# a34m41x register map
Vendor: ABOV Semiconductor Co., Ltd.; File version: 1.0
CPU: CM4 r0p1, little endian, MPU, FPU, VTOR, 4 interrupt priority bits
Registers are 32-bit, read-write, reset 0x0 unless marked. A register's access mark holds for its fields unless they carry their own. Offsets are from the block's base; [hi:lo] are bit positions; {n}, {i} and the like mark numbered series.

## PORTEN — General Port Access Enable
Base 0x40001FF0
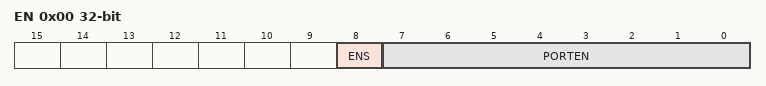
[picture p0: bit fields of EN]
0x00 EN wo (reset mask 0xFF) — Port Access Enable Register
  [8] ENS ro — Enable Status Bit
  [7:0] PORTEN — Port Access Enable bit, write sequence 0x15, 0x51

## DFMC — DATA FLASH MEMORY CONTROLLER
Base 0x41001000
0x00 CONF — Flash Memory Control Register
  [3:0] LATENCY — Flash Wait Value Bits
0x04 FLSKEY — Flash Memory Access Key Register
  [31:0] FKEY — Flash Memory Access Key, KEY1(0x01234567) -> KEY2(0x12345678) -> KEY3(0x23456789)
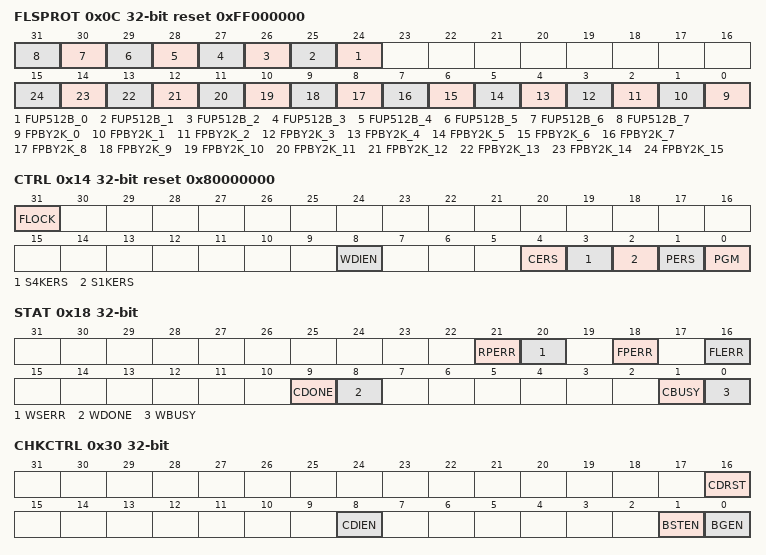
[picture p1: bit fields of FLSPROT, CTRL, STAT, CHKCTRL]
0x0C FLSPROT reset 0xFF000000 — Flash Memory Protection Register
  [n+24] FUP512B_{n} (n=0..7) — Flash upper 4KB Unprotection
  [n] FPBY2K_{n} (n=0..15) — Flash 2KB Protection
0x14 CTRL reset 0x80000000 — Flash Access Control Register
  [31] FLOCK — Flash Lock Setting Bit
  [8] WDIEN — Write done interrupt enable bit
  [4] CERS — Chip Erase Mode Bit
  [3] S4KERS — Sector 4KB Erase Mode
  [2] S1KERS — Sector 1KB Erase Mode
  [1] PERS — Page Erase Mode
  [0] PGM — Program Mode
0x18 STAT — Flash Access Status Register
  [21] RPERR — Read Protect Error(Auto Cleared)
  [20] WSERR — Write Sequence Error (Auto Cleared)
  [18] FPERR — Flash Protect Error (Auto Cleared)
  [16] FLERR — Flash Lock Error (Auto Cleared)
  [9] CDONE — Checksum Done Check (Auto Cleared)
  [8] WDONE — Write Done Check (Auto Cleared)
  [1] CBUSY ro — Checksum Busy Check
    0=Not Busy (Checksum Not Busy); 1=Busy (Checksum Busy)
  [0] WBUSY ro — Write Busy Check
    0=Not Busy (Checksum Not Busy); 1=Busy (Checksum Busy)
0x30 CHKCTRL — Flash Checksum Control Register
  [16] CDRST — Checksum Data Reset (Auto Cleared)
    0=No Effect; 1=Reset
  [8] CDIEN — Checksum Done Interrupt
    0=Disable; 1=Enable
  [1] BSTEN — Burst Mode
    0=Disable; 1=Enable
  [0] BGEN — Back Ground Mode
    0=Disable; 1=Enable
0x34 CHKDOUT — Flash Checksum Data Output Register
  [15:0] CDOUT ro — Flash Checksum Data Output bit
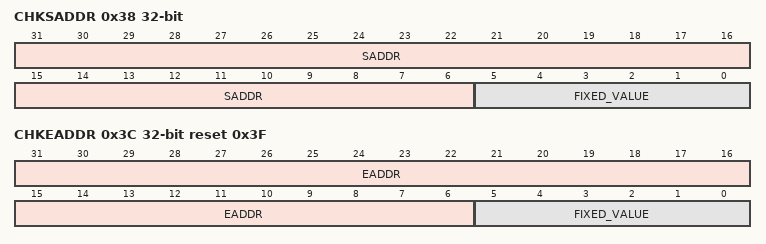
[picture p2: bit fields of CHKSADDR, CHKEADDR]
0x38 CHKSADDR — Flash Checksum Start Address Resgister
  [31:6] SADDR — Flash Checksum Start Address bit
  [5:0] FIXED_VALUE ro — Fixed Vaule
0x3C CHKEADDR reset 0x3F — Flash Checksum End Address Register
  [31:6] EADDR — Flash Checksum End Address bit
  [5:0] FIXED_VALUE ro

## DMA0 — Direct Memory Access Control
Base 0x40000400
Same registers: DMA{n} {0x40000400+0x10*n} (n=1..15)
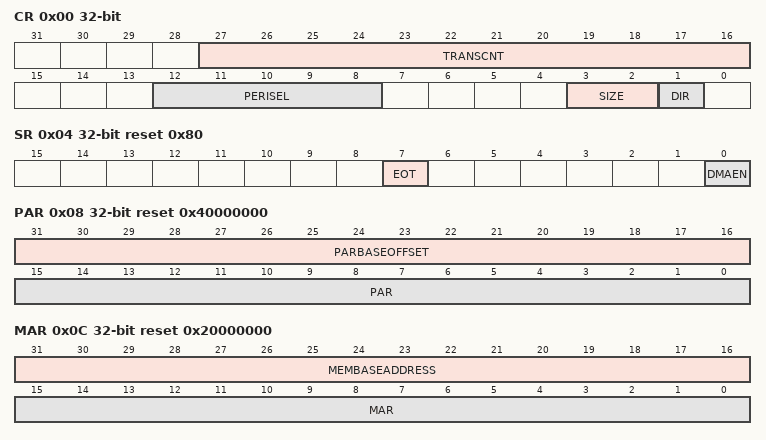
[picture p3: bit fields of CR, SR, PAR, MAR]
0x00 CR — DMA Control Register
  [27:16] TRANSCNT — DMA Transmit counter
  [12:8] PERISEL — Peripheral Selection Bit
  [3:2] SIZE — Bus Transmit Size
    0=Byte (transmit byte size); 1=half_word (transmit half word size); 2=word (transmit word size)
  [1] DIR — Transmit direction selection bit
    0=MEM-PERI (Memory->Peripheral); 1=PERI-MEM (Peripheral->Memory)
0x04 SR reset 0x80 — DMA Status Register
  [7] EOT ro — Transmit is over
  [0] DMAEN — DMA Enable Bit
0x08 PAR reset 0x40000000 — DMA Peripheral address register
  [31:16] PARBASEOFFSET ro — Peripheral Base Offset
  [15:0] PAR — Peripheral address bit
0x0C MAR reset 0x20000000 — DMA Memory address register
  [31:16] MEMBASEADDRESS ro — Memory Base Address
  [15:0] MAR — Purpose Memory Address

## WDT — WATCH-DOG TIMER
Base 0x40000200
0x00 LR — Watch-dog Timer Load Register
  [31:0] WDTLR — WDT Load Value Bits
0x04 CNT reset 0x7A12 — Watch-dog Timer Counter Register
  [31:0] WDTCNT ro — Watch-dog Timer Counter Value Bits
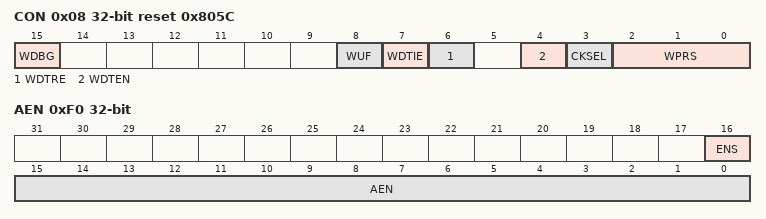
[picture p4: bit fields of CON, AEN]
0x08 CON reset 0x805C — Watch-dog Timer Control Register
  [15] WDBG — Watch-dog Timer Control in debugging mode
  [8] WUF — Watch-dog Timer Underflow Flag Bit, when write WDTLR register, this bit is cleared.
  [7] WDTIE — Watch-dog Timer Underflow Interrupt Enable bit
  [6] WDTRE — Watch-dog Timer Underflow Reset Enable bit
  [4] WDTEN — Watch-dog Timer Counter Enable bit
  [3] CKSEL — Watch-dog Timer Clock Source Selection Bit
  [2:0] WPRS — Watch-dog Timer Counter Clock Prescaler bit
    0=WDTCLKIN_DIV_BY_1 (WDT Input Clock divide by 1); 1=WDTCLKIN_DIV_BY_4 (WDT Input Clock divide by 4); 2=WDTCLKIN_DIV_BY_8 (WDT Input Clock divide by 8); 3=WDTCLKIN_DIV_BY_16 (WDT Input Clock divide by 16); 4=WDTCLKIN_DIV_BY_32 (WDT Input Clock divide by 32); 5=WDTCLKIN_DIV_BY_64 (WDT Input Clock divide by 64); 6=WDTCLKIN_DIV_BY_128 (WDT Input Clock divide by 128); 7=WDTCLKIN_DIV_BY_256 (WDT Input Clock divide by 256)
0xF0 AEN — Watch-dog Timer Master Lock/Reload Register
  [16] ENS ro — Enable status bit
  [15:0] AEN wo — WDT Master Lock Enable Register (Access = 0xA55A, Reload = 0x555A)

## Notices in the file
Copyright (C) 2012-2014 ARM Limited. All rights reserved.
Purpose: System Viewer Description (SVD) Example (Schema Version 1.1)
This is a description of a none-existent and incomplete device
for demonstration purposes only.
Redistribution and use in source and binary forms, with or without
modification, are permitted provided that the following conditions are met:
- Redistributions of source code must retain the above copyright
notice, this list of conditions and the following disclaimer.
- Redistributions in binary form must reproduce the above copyright
notice, this list of conditions and the following disclaimer in the
documentation and/or other materials provided with the distribution.
- Neither the name of ARM nor the names of its contributors may be used
to endorse or promote products derived from this software without
specific prior written permission.
THIS SOFTWARE IS PROVIDED BY THE COPYRIGHT HOLDERS AND CONTRIBUTORS "AS IS"
AND ANY EXPRESS OR IMPLIED WARRANTIES, INCLUDING, BUT NOT LIMITED TO, THE
IMPLIED WARRANTIES OF MERCHANTABILITY AND FITNESS FOR A PARTICULAR PURPOSE
ARE DISCLAIMED. IN NO EVENT SHALL COPYRIGHT HOLDERS AND CONTRIBUTORS BE
LIABLE FOR ANY DIRECT, INDIRECT, INCIDENTAL, SPECIAL, EXEMPLARY, OR
CONSEQUENTIAL DAMAGES (INCLUDING, BUT NOT LIMITED TO, PROCUREMENT OF
SUBSTITUTE GOODS OR SERVICES; LOSS OF USE, DATA, OR PROFITS; OR BUSINESS
INTERRUPTION) HOWEVER CAUSED AND ON ANY THEORY OF LIABILITY, WHETHER IN
CONTRACT, STRICT LIABILITY, OR TORT (INCLUDING NEGLIGENCE OR OTHERWISE)
ARISING IN ANY WAY OUT OF THE USE OF THIS SOFTWARE, EVEN IF ADVISED OF THE
POSSIBILITY OF SUCH DAMAGE.
